# BS2X register map
File version: 0.1
CPU: other r0p0, little endian, MPU, FPU, 3 interrupt priority bits
Registers are 32-bit, read-write, reset 0x0 unless marked. A register's access mark holds for its fields unless they carry their own. Offsets are from the block's base; [hi:lo] are bit positions; {n}, {i} and the like mark numbered series.

## GADC — 13-bit GADC (general ADC, v153)
Base 0x57036000
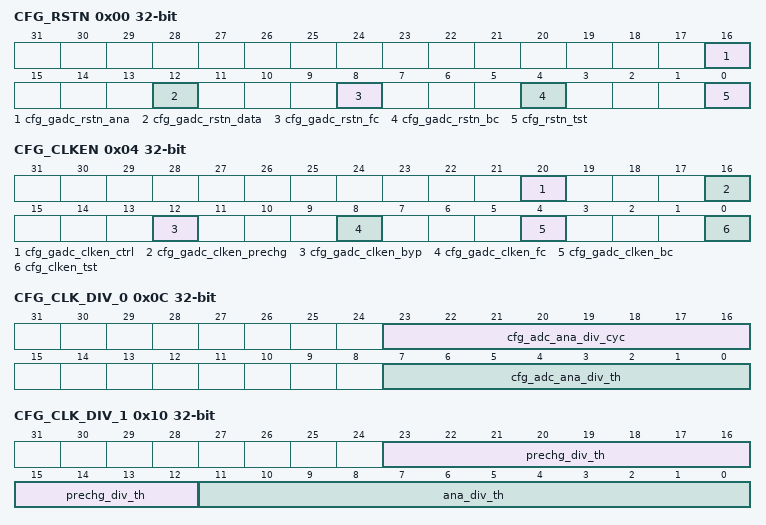
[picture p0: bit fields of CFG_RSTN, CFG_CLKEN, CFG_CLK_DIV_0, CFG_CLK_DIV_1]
0x00 CFG_RSTN
  [16] cfg_gadc_rstn_ana, [12] cfg_gadc_rstn_data, [8] cfg_gadc_rstn_fc, [4] cfg_gadc_rstn_bc, [0] cfg_rstn_tst
0x04 CFG_CLKEN
  [20] cfg_gadc_clken_ctrl, [16] cfg_gadc_clken_prechg, [12] cfg_gadc_clken_byp, [8] cfg_gadc_clken_fc, [4] cfg_gadc_clken_bc, [0] cfg_clken_tst
0x08 CFG_PRECHG_LEAD
0x0C CFG_CLK_DIV_0
  [23:16] cfg_adc_ana_div_cyc, [7:0] cfg_adc_ana_div_th
0x10 CFG_CLK_DIV_1
  [23:12] prechg_div_th, [11:0] ana_div_th
0x14 CFG_MANUAL_CLK_0
0x18 CFG_MANUAL_CLK_1
0x1C CFG_ISO
{0x30+4i} CFG_GADC_CTRL_{i} (i=0..4)
0x44 RPT_GADC_CTRL_0
0x48 CFG_GADC_CTRL_5
0x4C CFG_GADC_CTRL_6
0x50 RPT_GADC_CTRL_1
0x54 CFG_GADC_CTRL_7
0x58 RPT_GADC_CTRL_2
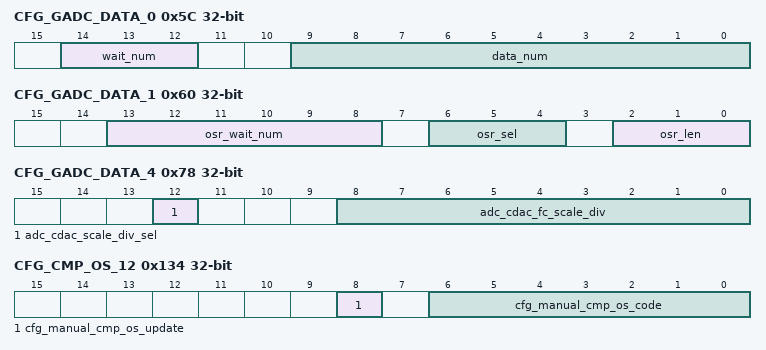
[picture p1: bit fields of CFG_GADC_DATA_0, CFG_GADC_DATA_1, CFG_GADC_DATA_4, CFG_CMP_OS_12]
0x5C CFG_GADC_DATA_0
  [14:12] wait_num, [9:0] data_num
0x60 CFG_GADC_DATA_1
  [13:8] osr_wait_num, [6:4] osr_sel, [2:0] osr_len
0x64 RPT_GADC_DATA_0
0x68 RPT_GADC_DATA_1
0x6C RPT_GADC_DATA_2 ro
  [17:0] sample_data
0x70 RPT_GADC_DATA_3 ro
  [0] single_sample_done
0x74 CFG_GADC_DATA_3
0x78 CFG_GADC_DATA_4
  [12] adc_cdac_scale_div_sel, [8:0] adc_cdac_fc_scale_div
0x7C RPT_GADC_DATA_4
{0x6C+4i} CFG_GADC_DATA_{i} (i=5..25)
{0xC0+4i} RPT_GADC_DATA_{i} (i=5..13)
{0x100+4i} CFG_CMP_OS_{i} (i=0..10)
0x12C RPT_CMP_OS_0
0x130 CFG_CMP_OS_11
0x134 CFG_CMP_OS_12
  [8] cfg_manual_cmp_os_update, [6:0] cfg_manual_cmp_os_code
0x138 RPT_CMP_OS_2
{0x150+4i} CFG_CDAC_FC0_{i} (i=0..5)
0x168 RPT_CDAC_FC0_0
{0x154+4i} CFG_CDAC_FC0_{i} (i=6..14)
{0x190+4i} CFG_CDAC_FC1_{i} (i=0..3)
0x1A0 RPT_CDAC_FC1_0
0x1A4 RPT_CDAC_FC1_3
{0x1A4+4i} RPT_CDAC_FC3_{i} (i=1..18)
{0x200+4i} CFG_DCOC_CAL_{i} (i=0..8)
0x224 RPT_DCOC_CAL_0
0x228 CFG_DCOC_CAL_12
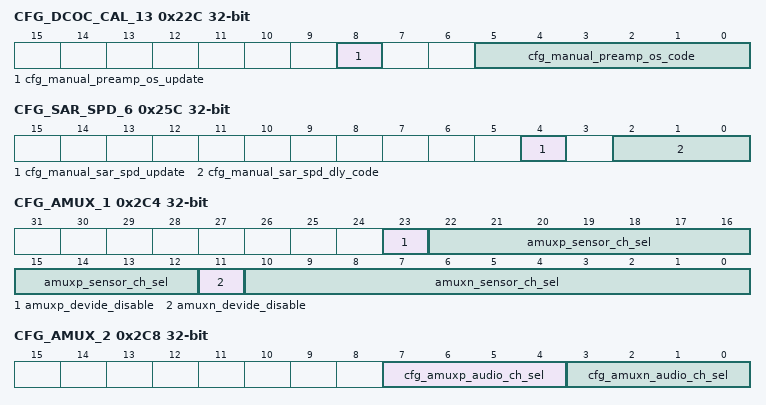
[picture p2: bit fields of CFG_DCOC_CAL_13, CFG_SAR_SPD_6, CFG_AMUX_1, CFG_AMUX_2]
0x22C CFG_DCOC_CAL_13
  [8] cfg_manual_preamp_os_update, [5:0] cfg_manual_preamp_os_code
0x230 RPT_DCOC_CAL_1
{0x240+4i} CFG_SAR_SPD_{i} (i=0..4)
0x254 RPT_SAR_SPD_0
0x258 RPT_SAR_SPD_1
0x25C CFG_SAR_SPD_6
  [4] cfg_manual_sar_spd_update, [2:0] cfg_manual_sar_spd_dly_code
0x260 RPT_SAR_SPD_2
{0x280+4i} CFG_RC_CAL_{i} (i=0..4)
0x294 RPT_RC_CAL_0
0x298 RPT_RC_CAL_1
{0x288+4i} CFG_RC_CAL_{i} (i=5..8)
0x2AC RPT_RC_CAL_2
0x2B0 RPT_RC_CAL_3
0x2C0 CFG_AMUX_0
0x2C4 CFG_AMUX_1
  [23] amuxp_devide_disable, [22:12] amuxp_sensor_ch_sel, [11] amuxn_devide_disable, [10:0] amuxn_sensor_ch_sel
0x2C8 CFG_AMUX_2
  [7:4] cfg_amuxp_audio_ch_sel, [3:0] cfg_amuxn_audio_ch_sel
{0x2C0+4i} CFG_AMUX_{i} (i=3..5)
0x2D8 RPT_AMUX_0
0x2F0 CFG_TST_0
0x2F4 CFG_TST_1
  [2:0] diag_node
0x2F8 CFG_CMP_0
0x2FC CFG_CMP_1
0x300 RPT_CMP_0
0x304 RPT_CMP_1
0x3D0 CFG_RX_SCRATCH
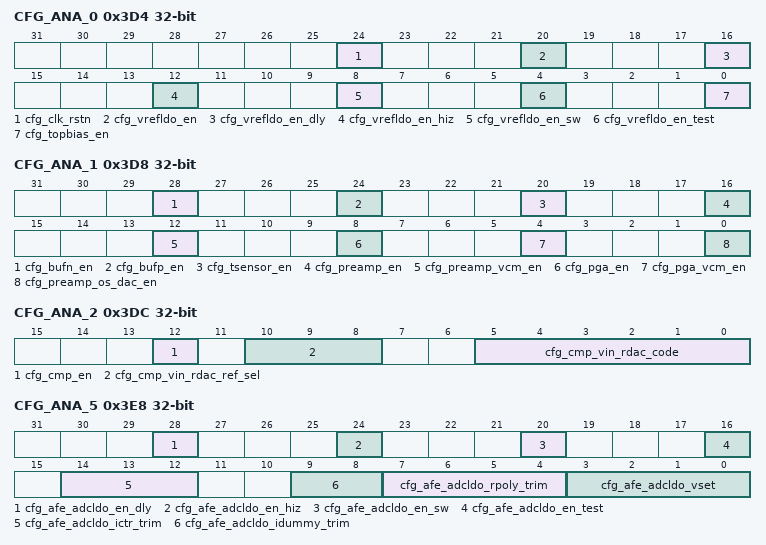
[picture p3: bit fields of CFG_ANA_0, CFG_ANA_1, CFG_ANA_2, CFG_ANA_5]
0x3D4 CFG_ANA_0
  [24] cfg_clk_rstn, [20] cfg_vrefldo_en, [16] cfg_vrefldo_en_dly, [12] cfg_vrefldo_en_hiz, [8] cfg_vrefldo_en_sw, [4] cfg_vrefldo_en_test, [0] cfg_topbias_en
0x3D8 CFG_ANA_1
  [28] cfg_bufn_en, [24] cfg_bufp_en, [20] cfg_tsensor_en, [16] cfg_preamp_en, [12] cfg_preamp_vcm_en, [8] cfg_pga_en, [4] cfg_pga_vcm_en, [0] cfg_preamp_os_dac_en
0x3DC CFG_ANA_2
  [12] cfg_cmp_en, [10:8] cfg_cmp_vin_rdac_ref_sel, [5:0] cfg_cmp_vin_rdac_code
0x3E0 CFG_ANA_3
0x3E4 CFG_ANA_4
  [0] cfg_afe_adcldo_en
0x3E8 CFG_ANA_5
  [28] cfg_afe_adcldo_en_dly, [24] cfg_afe_adcldo_en_hiz, [20] cfg_afe_adcldo_en_sw, [16] cfg_afe_adcldo_en_test, [14:12] cfg_afe_adcldo_ictr_trim, [9:8] cfg_afe_adcldo_idummy_trim, [7:4] cfg_afe_adcldo_rpoly_trim, [3:0] cfg_afe_adcldo_vset
0x3EC CFG_ANA_6
  [0] cfg_afe_afeldo_en
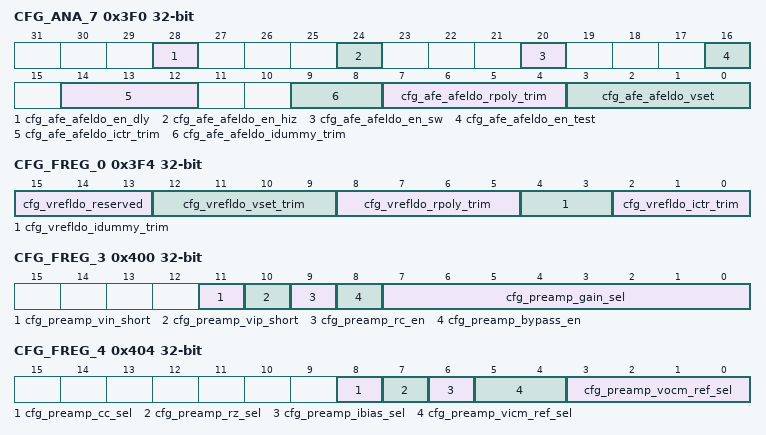
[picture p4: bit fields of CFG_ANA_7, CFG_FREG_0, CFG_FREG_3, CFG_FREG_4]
0x3F0 CFG_ANA_7
  [28] cfg_afe_afeldo_en_dly, [24] cfg_afe_afeldo_en_hiz, [20] cfg_afe_afeldo_en_sw, [16] cfg_afe_afeldo_en_test, [14:12] cfg_afe_afeldo_ictr_trim, [9:8] cfg_afe_afeldo_idummy_trim, [7:4] cfg_afe_afeldo_rpoly_trim, [3:0] cfg_afe_afeldo_vset
0x3F4 CFG_FREG_0
  [15:13] cfg_vrefldo_reserved, [12:9] cfg_vrefldo_vset_trim, [8:5] cfg_vrefldo_rpoly_trim, [4:3] cfg_vrefldo_idummy_trim, [2:0] cfg_vrefldo_ictr_trim
0x3F8 CFG_FREG_1
0x3FC CFG_FREG_2
0x400 CFG_FREG_3
  [11] cfg_preamp_vin_short, [10] cfg_preamp_vip_short, [9] cfg_preamp_rc_en, [8] cfg_preamp_bypass_en, [7:0] cfg_preamp_gain_sel
0x404 CFG_FREG_4
  [8] cfg_preamp_cc_sel, [7] cfg_preamp_rz_sel, [6] cfg_preamp_ibias_sel, [5:4] cfg_preamp_vicm_ref_sel, [3:0] cfg_preamp_vocm_ref_sel
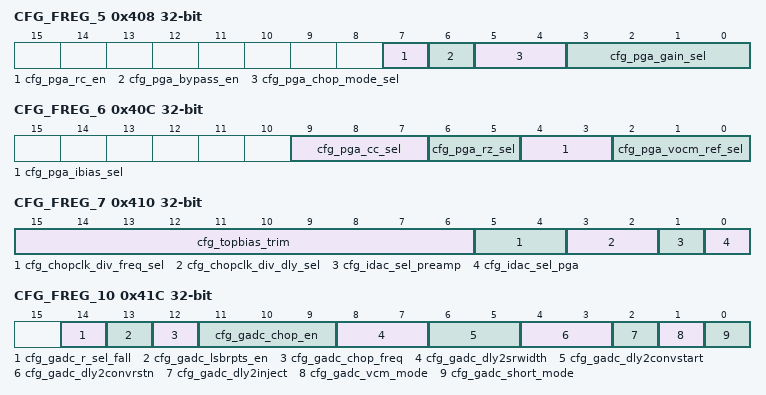
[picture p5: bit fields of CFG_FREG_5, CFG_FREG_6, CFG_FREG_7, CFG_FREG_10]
0x408 CFG_FREG_5
  [7] cfg_pga_rc_en, [6] cfg_pga_bypass_en, [5:4] cfg_pga_chop_mode_sel, [3:0] cfg_pga_gain_sel
0x40C CFG_FREG_6
  [9:7] cfg_pga_cc_sel, [6:5] cfg_pga_rz_sel, [4:3] cfg_pga_ibias_sel, [2:0] cfg_pga_vocm_ref_sel
0x410 CFG_FREG_7
  [15:6] cfg_topbias_trim, [5:4] cfg_chopclk_div_freq_sel, [3:2] cfg_chopclk_div_dly_sel, [1] cfg_idac_sel_preamp, [0] cfg_idac_sel_pga
0x414 CFG_FREG_8
0x418 CFG_FREG_9
0x41C CFG_FREG_10
  [14] cfg_gadc_r_sel_fall, [13] cfg_gadc_lsbrpts_en, [12] cfg_gadc_chop_freq, [11:9] cfg_gadc_chop_en, [8:7] cfg_gadc_dly2srwidth, [6:5] cfg_gadc_dly2convstart, [4:3] cfg_gadc_dly2convrstn, [2] cfg_gadc_dly2inject, [1] cfg_gadc_vcm_mode, [0] cfg_gadc_short_mode
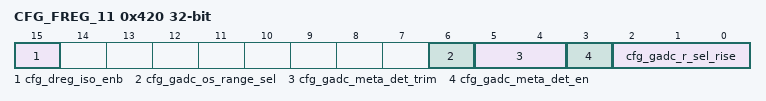
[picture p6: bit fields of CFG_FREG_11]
0x420 CFG_FREG_11
  [15] cfg_dreg_iso_enb, [6] cfg_gadc_os_range_sel, [5:4] cfg_gadc_meta_det_trim, [3] cfg_gadc_meta_det_en, [2:0] cfg_gadc_r_sel_rise
